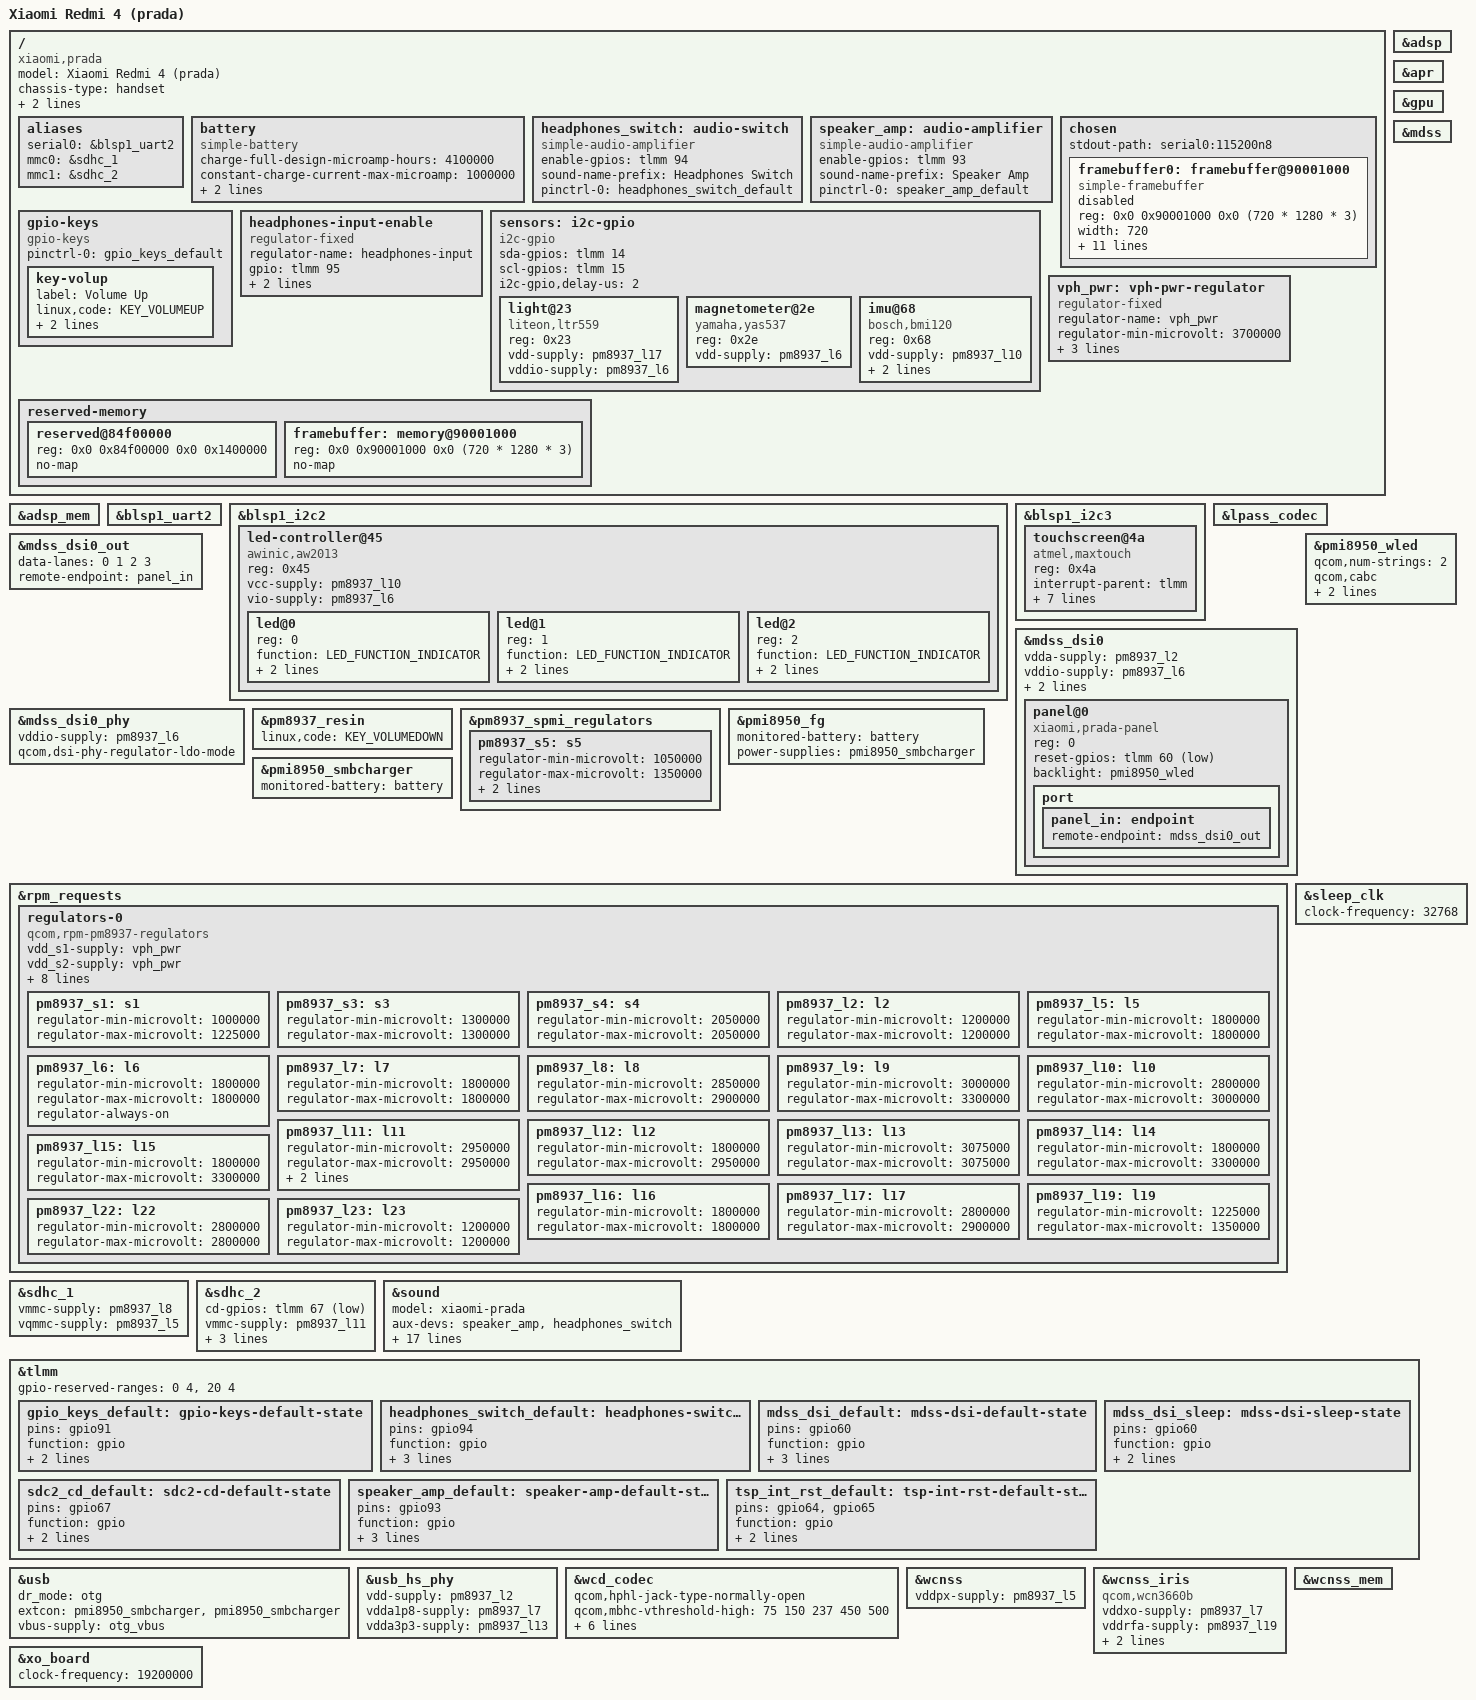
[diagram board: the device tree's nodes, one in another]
// SPDX-License-Identifier: BSD-3-Clause
/*
 * Copyright (c) 2025, Vasiliy Doylov (NekoCWD) <nekodevelopper@gmail.com>
 */
/dts-v1/;

#include <dt-bindings/arm/qcom,ids.h>
#include <dt-bindings/gpio/gpio.h>
#include <dt-bindings/leds/common.h>

#include "msm8937.dtsi"
#include "pm8937.dtsi"
#include "pmi8950.dtsi"
#include "msm8937-qdsp6.dtsi"

/delete-node/ &qseecom_mem;

/ {
	model = "Xiaomi Redmi 4 (prada)";
	compatible = "xiaomi,prada", "qcom,msm8937";
	chassis-type = "handset";

	qcom,msm-id = <QCOM_ID_MSM8937 0x0>;
	qcom,board-id = <QCOM_BOARD_ID_MTP 0x0>;

	aliases {
		serial0 = &blsp1_uart2;
		mmc0 = &sdhc_1;
		mmc1 = &sdhc_2;
	};

	battery: battery {
		compatible = "simple-battery";

		charge-full-design-microamp-hours = <4100000>;
		constant-charge-current-max-microamp = <1000000>;
		voltage-min-design-microvolt = <3400000>;
		voltage-max-design-microvolt = <4400000>;
	};

	headphones_switch: audio-switch {
		compatible = "simple-audio-amplifier";
		enable-gpios = <&tlmm 94 GPIO_ACTIVE_HIGH>;
		sound-name-prefix = "Headphones Switch";
		pinctrl-0 = <&headphones_switch_default>;
		pinctrl-names = "default";
	};

	speaker_amp: audio-amplifier {
		compatible = "simple-audio-amplifier";
		enable-gpios = <&tlmm 93 GPIO_ACTIVE_HIGH>;
		sound-name-prefix = "Speaker Amp";
		pinctrl-0 = <&speaker_amp_default>;
		pinctrl-names = "default";
	};

	chosen {
		#address-cells = <2>;
		#size-cells = <2>;
		ranges;

		stdout-path = "serial0:115200n8";

		framebuffer0: framebuffer@90001000 {
			compatible = "simple-framebuffer";
			reg = <0x0 0x90001000 0x0 (720 * 1280 * 3)>;
			width = <720>;
			height = <1280>;
			stride = <(720 * 3)>;
			format = "r8g8b8";

			clocks = <&gcc GCC_MDSS_AHB_CLK>,
				 <&gcc GCC_MDSS_AXI_CLK>,
				 <&gcc GCC_MDSS_VSYNC_CLK>,
				 <&gcc GCC_MDSS_MDP_CLK>,
				 <&gcc GCC_MDSS_BYTE0_CLK>,
				 <&gcc GCC_MDSS_PCLK0_CLK>,
				 <&gcc GCC_MDSS_ESC0_CLK>;
			power-domains = <&gcc MDSS_GDSC>;
			status = "disabled";
		};
	};

	gpio-keys {
		compatible = "gpio-keys";

		pinctrl-0 = <&gpio_keys_default>;
		pinctrl-names = "default";

		key-volup {
			label = "Volume Up";
			linux,code = <KEY_VOLUMEUP>;
			gpios = <&tlmm 91 GPIO_ACTIVE_LOW>;
			debounce-interval = <15>;
		};
	};

	headphones-input-enable {
		compatible = "regulator-fixed";
		regulator-name = "headphones-input";
		gpio = <&tlmm 95 GPIO_ACTIVE_HIGH>;
		enable-active-high;
		regulator-always-on;
	};

	sensors: i2c-gpio {
		// i2c4 is protected, bitbanging
		compatible = "i2c-gpio";
		sda-gpios = <&tlmm 14 (GPIO_ACTIVE_HIGH|GPIO_OPEN_DRAIN)>;
		scl-gpios = <&tlmm 15 (GPIO_ACTIVE_HIGH|GPIO_OPEN_DRAIN)>;
		i2c-gpio,delay-us = <2>;        /* ~100 kHz */
		#address-cells = <1>;
		#size-cells = <0>;

		light@23 {
			compatible = "liteon,ltr559";
			reg = <0x23>;

			vdd-supply = <&pm8937_l17>;
			vddio-supply = <&pm8937_l6>;
		};

		magnetometer@2e {
			compatible = "yamaha,yas537";
			reg = <0x2e>;

			vdd-supply = <&pm8937_l6>;
		};

		imu@68 {
			compatible = "bosch,bmi120";
			reg = <0x68>;

			vdd-supply = <&pm8937_l10>;
			vddio-supply = <&pm8937_l6>;

			mount-matrix =	"0", "-1", "0",
					"1", "0", "0",
					"0", "0", "1";
		};
	};

	reserved-memory {
		reserved@84f00000 {
			reg = <0x0 0x84f00000 0x0 0x1400000>;
			no-map;
		};

		framebuffer: memory@90001000 {
			reg = <0x0 0x90001000 0x0 (720 * 1280 * 3)>;
			no-map;
		};
	};

	vph_pwr: vph-pwr-regulator {
		compatible = "regulator-fixed";
		regulator-name = "vph_pwr";
		regulator-min-microvolt = <3700000>;
		regulator-max-microvolt = <3700000>;
		regulator-always-on;
		regulator-boot-on;
	};
};

&adsp {
	status = "okay";
};

&adsp_mem {
	status = "okay";
};

&apr {
	status = "okay";
};

&blsp1_uart2 {
	status = "okay";
};

&blsp1_i2c2 {
	status = "okay";

	led-controller@45 {
		compatible = "awinic,aw2013";
		reg = <0x45>;
		#address-cells = <1>;
		#size-cells = <0>;

		vcc-supply = <&pm8937_l10>;
		vio-supply = <&pm8937_l6>;

		led@0 {
			reg = <0>;
			function = LED_FUNCTION_INDICATOR;
			led-max-microamp = <5000>;
			color = <LED_COLOR_ID_RED>;
		};

		led@1 {
			reg = <1>;
			function = LED_FUNCTION_INDICATOR;
			led-max-microamp = <5000>;
			color = <LED_COLOR_ID_GREEN>;
		};

		led@2 {
			reg = <2>;
			function = LED_FUNCTION_INDICATOR;
			led-max-microamp = <5000>;
			color = <LED_COLOR_ID_BLUE>;
		};
	};
};

&blsp1_i2c3 {
	status = "okay";

	touchscreen@4a {
		compatible = "atmel,maxtouch";
		reg = <0x4a>;
		interrupt-parent = <&tlmm>;
		interrupts = <65 IRQ_TYPE_LEVEL_LOW>;

		vdd-supply = <&pm8937_l6>;
		vdda-supply = <&pm8937_l10>;

		reset-gpios = <&tlmm 64 GPIO_ACTIVE_LOW>;

		pinctrl-0 = <&tsp_int_rst_default>;
		pinctrl-names = "default";

		linux,keycodes = <KEY_APPSELECT KEY_HOME KEY_BACK>;
	};
};

&gpu {
	status = "okay";
};

&lpass_codec{
	status = "okay";
};

&mdss {
	status = "okay";
};

&mdss_dsi0 {
	vdda-supply = <&pm8937_l2>;
	vddio-supply = <&pm8937_l6>;

	pinctrl-0 = <&mdss_dsi_default>;
	pinctrl-1 = <&mdss_dsi_sleep>;
	pinctrl-names = "default", "sleep";

	status = "okay";

	panel@0 {
		compatible = "xiaomi,prada-panel";
		reg = <0>;

		reset-gpios = <&tlmm 60 GPIO_ACTIVE_LOW>;
		backlight = <&pmi8950_wled>;

		port {
			panel_in: endpoint {
				remote-endpoint = <&mdss_dsi0_out>;
			};
		};
	};
};

&mdss_dsi0_out {
	data-lanes = <0 1 2 3>;
	remote-endpoint = <&panel_in>;
};

&mdss_dsi0_phy {
	vddio-supply = <&pm8937_l6>;
	qcom,dsi-phy-regulator-ldo-mode;

	status = "okay";
};

&pm8937_resin {
	linux,code = <KEY_VOLUMEDOWN>;
	status = "okay";
};

&pm8937_spmi_regulators {
	pm8937_s5: s5 {
		regulator-min-microvolt = <1050000>;
		regulator-max-microvolt = <1350000>;
		regulator-always-on;
		regulator-boot-on;
	};
};

&pmi8950_fg {
	monitored-battery = <&battery>;
	power-supplies = <&pmi8950_smbcharger>;
	status = "okay";
};

&pmi8950_smbcharger {
	monitored-battery = <&battery>;
	status = "okay";
};

&pmi8950_wled {
	qcom,num-strings = <2>;
	qcom,cabc;
	qcom,current-limit-microamp = <20000>;
	qcom,ovp-millivolt = <29600>;

	status = "okay";
};

&rpm_requests {
	regulators-0 {
		compatible = "qcom,rpm-pm8937-regulators";

		vdd_s1-supply = <&vph_pwr>;
		vdd_s2-supply = <&vph_pwr>;
		vdd_s3-supply = <&vph_pwr>;
		vdd_s4-supply = <&vph_pwr>;

		vdd_l1_l19-supply = <&pm8937_s3>;
		vdd_l2_l23-supply = <&pm8937_s3>;
		vdd_l3-supply = <&pm8937_s3>;
		vdd_l4_l5_l6_l7_l16-supply = <&pm8937_s4>;
		vdd_l8_l11_l12_l17_l22-supply = <&vph_pwr>;
		vdd_l9_l10_l13_l14_l15_l18-supply = <&vph_pwr>;

		pm8937_s1: s1 {
			regulator-min-microvolt = <1000000>;
			regulator-max-microvolt = <1225000>;
		};

		pm8937_s3: s3 {
			regulator-min-microvolt = <1300000>;
			regulator-max-microvolt = <1300000>;
		};

		pm8937_s4: s4 {
			regulator-min-microvolt = <2050000>;
			regulator-max-microvolt = <2050000>;
		};

		pm8937_l2: l2 {
			regulator-min-microvolt = <1200000>;
			regulator-max-microvolt = <1200000>;
		};

		pm8937_l5: l5 {
			regulator-min-microvolt = <1800000>;
			regulator-max-microvolt = <1800000>;
		};

		pm8937_l6: l6 {
			regulator-min-microvolt = <1800000>;
			regulator-max-microvolt = <1800000>;
			regulator-always-on;
		};

		pm8937_l7: l7 {
			regulator-min-microvolt = <1800000>;
			regulator-max-microvolt = <1800000>;
		};

		pm8937_l8: l8 {
			regulator-min-microvolt = <2850000>;
			regulator-max-microvolt = <2900000>;
		};

		pm8937_l9: l9 {
			regulator-min-microvolt = <3000000>;
			regulator-max-microvolt = <3300000>;
		};

		pm8937_l10: l10 {
			regulator-min-microvolt = <2800000>;
			regulator-max-microvolt = <3000000>;
		};

		pm8937_l11: l11 {
			regulator-min-microvolt = <2950000>;
			regulator-max-microvolt = <2950000>;
			regulator-allow-set-load;
			regulator-system-load = <200000>;
		};

		pm8937_l12: l12 {
			regulator-min-microvolt = <1800000>;
			regulator-max-microvolt = <2950000>;
		};

		pm8937_l13: l13 {
			regulator-min-microvolt = <3075000>;
			regulator-max-microvolt = <3075000>;
		};

		pm8937_l14: l14 {
			regulator-min-microvolt = <1800000>;
			regulator-max-microvolt = <3300000>;
		};

		pm8937_l15: l15 {
			regulator-min-microvolt = <1800000>;
			regulator-max-microvolt = <3300000>;
		};

		pm8937_l16: l16 {
			regulator-min-microvolt = <1800000>;
			regulator-max-microvolt = <1800000>;
		};

		pm8937_l17: l17 {
			regulator-min-microvolt = <2800000>;
			regulator-max-microvolt = <2900000>;
		};

		pm8937_l19: l19 {
			regulator-min-microvolt = <1225000>;
			regulator-max-microvolt = <1350000>;
		};

		pm8937_l22: l22 {
			regulator-min-microvolt = <2800000>;
			regulator-max-microvolt = <2800000>;
		};

		pm8937_l23: l23 {
			regulator-min-microvolt = <1200000>;
			regulator-max-microvolt = <1200000>;
		};
	};
};

&sdhc_1 {
	vmmc-supply = <&pm8937_l8>;
	vqmmc-supply = <&pm8937_l5>;
	status = "okay";
};

&sdhc_2 {
	cd-gpios = <&tlmm 67 GPIO_ACTIVE_LOW>;
	vmmc-supply = <&pm8937_l11>;
	vqmmc-supply = <&pm8937_l12>;
	pinctrl-0 = <&sdc2_default &sdc2_cd_default>;
	pinctrl-1 = <&sdc2_sleep &sdc2_cd_default>;
	pinctrl-names = "default", "sleep";
	status = "okay";
};

&sleep_clk {
	clock-frequency = <32768>;
};

&sound {
	model = "xiaomi-prada";

	aux-devs = <&speaker_amp>, <&headphones_switch>;
	widgets =
		"Speaker", "Speaker",
		"Headphone", "Headphones";
	pin-switches = "Speaker", "Headphones";
	audio-routing =
		"Speaker", "Speaker Amp OUTL",
		"Speaker", "Speaker Amp OUTR",
		"Speaker Amp INL", "HPHR",
		"Speaker Amp INR", "HPHR",
		"Headphones", "Headphones Switch OUTL",
		"Headphones", "Headphones Switch OUTR",
		"Headphones Switch INL", "HPHL",
		"Headphones Switch INR", "HPHR",
		"AMIC1", "MIC BIAS External1",
		"AMIC2", "MIC BIAS Internal2",
		"AMIC3", "MIC BIAS External1",
		"MM_DL1", "MultiMedia1 Playback",
		"MM_DL3", "MultiMedia3 Playback",
		"MM_DL4", "MultiMedia4 Playback",
		"MultiMedia2 Capture", "MM_UL2";

	status = "okay";
};

&tlmm {
	gpio-reserved-ranges = <0 4>, <20 4>;

	gpio_keys_default: gpio-keys-default-state {
		pins = "gpio91";
		function = "gpio";
		drive-strength = <2>;
		bias-pull-up;
	};

	headphones_switch_default: headphones-switch-default-state {
		pins = "gpio94";
		function = "gpio";
		drive-strength = <2>;
		bias-disable;
		output-low;
	};

	mdss_dsi_default: mdss-dsi-default-state {
		pins = "gpio60";
		function = "gpio";
		drive-strength = <8>;
		bias-disable;
		output-high;
	};

	mdss_dsi_sleep: mdss-dsi-sleep-state {
		pins = "gpio60";
		function = "gpio";
		drive-strength = <2>;
		bias-pull-down;
	};

	sdc2_cd_default: sdc2-cd-default-state {
		pins = "gpio67";
		function = "gpio";
		drive-strength = <2>;
		bias-disable;
	};

	speaker_amp_default: speaker-amp-default-state {
		pins = "gpio93";
		function = "gpio";
		drive-strength = <2>;
		bias-disable;
		output-low;
	};

	tsp_int_rst_default: tsp-int-rst-default-state {
		pins = "gpio64", "gpio65";
		function = "gpio";
		drive-strength = <8>;
		bias-pull-up;
	};
};

&usb {
	dr_mode = "otg";
	extcon = <&pmi8950_smbcharger>, <&pmi8950_smbcharger>;
	vbus-supply = <&otg_vbus>;
	status = "okay";
};

&usb_hs_phy {
	vdd-supply = <&pm8937_l2>;
	vdda1p8-supply = <&pm8937_l7>;
	vdda3p3-supply = <&pm8937_l13>;
	status = "okay";
};

&wcd_codec {
	qcom,hphl-jack-type-normally-open;
	/*
	* MBHC values ​​are copied from xiaomi-markw dts.
	* They are incorrect, but headphone and microphone detection works.
	*/
	qcom,mbhc-vthreshold-high = <75 150 237 450 500>;
	qcom,mbhc-vthreshold-low = <75 150 237 450 500>;
	qcom,micbias1-ext-cap;
	qcom,micbias2-ext-cap;

	vdd-cdc-io-supply = <&pm8937_l5>;
	vdd-cdc-tx-rx-cx-supply = <&pm8937_s4>;
	vdd-micbias-supply = <&pm8937_l13>;
	status = "okay";
};

&wcnss {
	vddpx-supply = <&pm8937_l5>;
	status = "okay";

};

&wcnss_iris {
	compatible = "qcom,wcn3660b";
	vddxo-supply = <&pm8937_l7>;
	vddrfa-supply = <&pm8937_l19>;
	vddpa-supply = <&pm8937_l9>;
	vdddig-supply = <&pm8937_l5>;
};

&wcnss_mem {
	status = "okay";
};

&xo_board {
	clock-frequency = <19200000>;
};
